# NAVSS0_MAILBOX1_10_ALIAS64K_MAILBOX1_CFG_REGS10 register map
Vendor: Texas Instruments
Peripheral module from a debugger description file (folder J721S2).
Registers are 32-bit, read-write, reset 0x0 unless marked. A register's access mark holds for its fields unless they carry their own. Offsets are as the file gives them; lines under a group give offsets from that group; [hi:lo] are bit positions; {n}, {i} and the like mark numbered series; 'fields as' and 'values as' point back to an identical list; <NAME> marks a mode.

## NAVSS0_MAILBOX1_10_ALIAS64K_MAILBOX1_CFG_REGS10
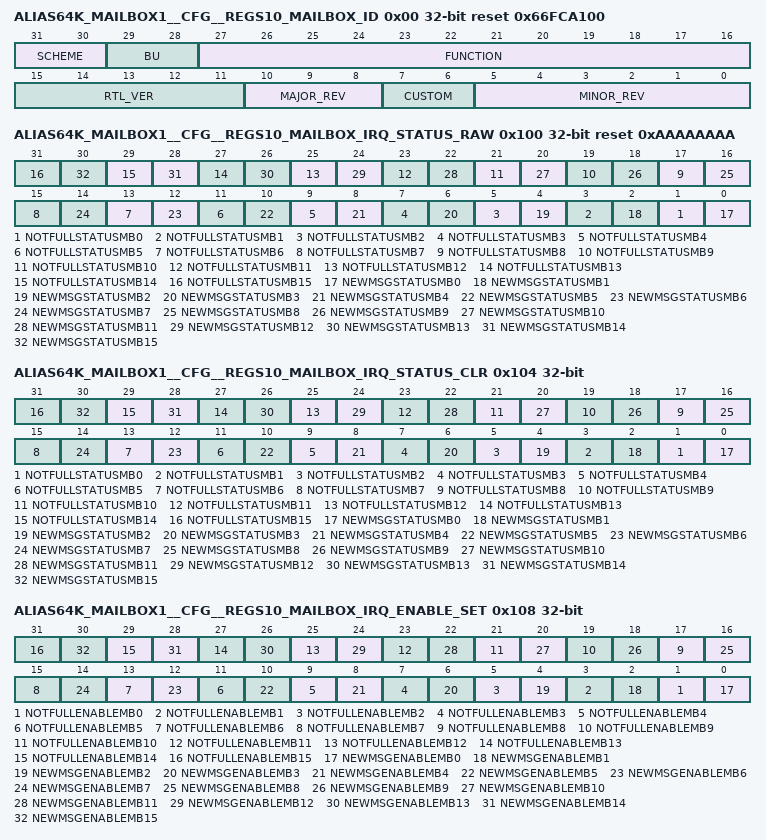
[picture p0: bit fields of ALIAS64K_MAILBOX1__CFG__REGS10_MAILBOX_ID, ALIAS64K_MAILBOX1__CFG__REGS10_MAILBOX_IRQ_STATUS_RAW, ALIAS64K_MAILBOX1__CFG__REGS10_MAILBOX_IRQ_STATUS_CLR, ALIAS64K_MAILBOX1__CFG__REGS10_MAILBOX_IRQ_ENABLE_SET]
0x00 ALIAS64K_MAILBOX1__CFG__REGS10_MAILBOX_ID ro reset 0x66FCA100 — This is the standard TI peripheral ID register that exists at address 0 in the peripheral space
  [31:30] SCHEME — Used to distinguish which ID numbering scheme is used.
  [29:28] BU — BU identifier
  [27:16] FUNCTION — Module family.
  [15:11] RTL_VER — RTL version. R of X.Y.R.Z
  [10:8] MAJOR_REV — Major revision. X of X.Y.R.Z
  [7:6] CUSTOM — Special version number
  [5:0] MINOR_REV — Minor revision. Y of X.Y.R.Z
0x10 ALIAS64K_MAILBOX1__CFG__REGS10_MAILBOX_SYSCONFIG — This register contains parameters to control the whole Mailbox system. Provided for backwards compatibility with OMAP Mailbox. Only contains the soft reset.
  [0] SOFT_RESET — Module Software Reset The bit is automatically reset by the hardware. During reads, it always returns 0. It has the same effect as the hardware reset. Writing a 0 has no effect. Writing a 1 will start a soft reset sequence and empty all the mailboxes
0x40 ALIAS64K_MAILBOX1__CFG__REGS10_MAILBOX_MESSAGE — The message register stores the next to-be-read message of the mailbox. Read: Reads the next available message. Write: Add a message to this mailbox queue.
  [31:0] MESSAGE_VALUE — Message in Mailbox [a]
0x80 ALIAS64K_MAILBOX1__CFG__REGS10_MAILBOX_FIFOSTATUS ro — The FIFO status register has the status of the Mailbox[a] FIFO
  [0] FIFO_FULL — Full flag for Mailbox m
0xC0 ALIAS64K_MAILBOX1__CFG__REGS10_MAILBOX_MSGSTATUS ro — The message status register has the status of the messages in Mailbox[a]
  [2:0] NUM_MESSAGES — Number of messages in Mailbox[a]
0x100 ALIAS64K_MAILBOX1__CFG__REGS10_MAILBOX_IRQ_STATUS_RAW reset 0xAAAAAAAA — The interrupt status register has the status for each event that may be responsible for the generation of an interrupt to the corresponding user . Software may also write 1 to a given bit to set this bit to test interrupt generation. It will activate the status bit for two cycles. This may still be masked, however. Write 0 has no effect.
  [2n+1] NOTFULLSTATUSMB{n} (n=0..15) — 1 if Mailbox {n} is not full
  [2n] NEWMSGSTATUSMB{n} (n=0..15) — 1 if there are messages present in Mailbox {n}
0x104 ALIAS64K_MAILBOX1__CFG__REGS10_MAILBOX_IRQ_STATUS_CLR — The interrupt status register has the status for each event that may be responsible for the generation of an interrupt to the corresponding user combined with the corresponding MASK information. Software may also write 1 to a given bit to clear this bit. However, if the hardware still has pending, enabled events, the interrupt will fire again in two cycles. Write 0 has no effect.
  [2n+1] NOTFULLSTATUSMB{n} (n=0..15) — 1 if Mailbox {n} is not full and this interrupt bit is enabled
  [2n] NEWMSGSTATUSMB{n} (n=0..15) — 1 if there are messages present in Mailbox {n} and this interrupt bit is enabled
0x108 ALIAS64K_MAILBOX1__CFG__REGS10_MAILBOX_IRQ_ENABLE_SET — The interrupt enable register allows software to mask/unmask the module internal source of interrupt for the user [a]. Read value is the current enable bits for each interrupt source. Write 1 to a bit enables an interrupt source. Write 0 has no effect.
  [2n+1] NOTFULLENABLEMB{n} (n=0..15) — Read value is current enable state for this interrupt. Write 1 enables the interrupt. Write 0 does nothing.
  [2n] NEWMSGENABLEMB{n} (n=0..15) — Read value is current enable state for this interrupt. Write 1 enables the interrupt. Write 0 does nothing.
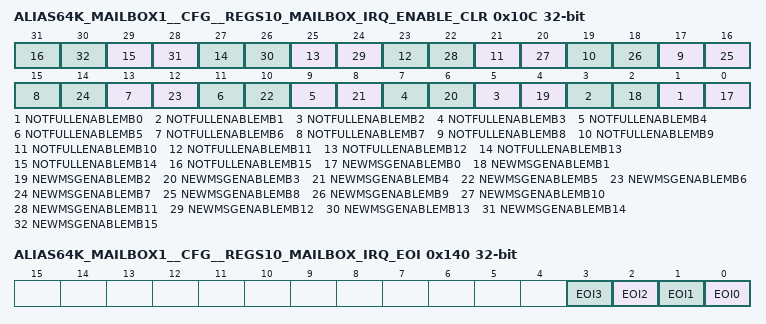
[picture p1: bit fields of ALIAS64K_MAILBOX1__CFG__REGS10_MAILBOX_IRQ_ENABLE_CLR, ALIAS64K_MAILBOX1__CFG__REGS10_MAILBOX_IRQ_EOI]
0x10C ALIAS64K_MAILBOX1__CFG__REGS10_MAILBOX_IRQ_ENABLE_CLR — The interrupt enable register allows software to mask/unmask the module internal source of interrupt for the user [a]. Read value is the current enable bits for each interrupt sourc. Write 1 to a bit disables an interrupt source. Write 0 has no effect.
  [2n+1] NOTFULLENABLEMB{n} (n=0..15) — Read value is current enable state for this interrupt. Write 1 disables the interrupt. Write 0 does nothing.
  [2n] NEWMSGENABLEMB{n} (n=0..15) — Read value is current enable state for this interrupt. Write 1 disables the interrupt. Write 0 does nothing.
0x140 ALIAS64K_MAILBOX1__CFG__REGS10_MAILBOX_IRQ_EOI wo — This is the EOI register with which the software is enabled to do the interrupt clearance.
  [n] EOI{n} (n=0..3) — Software EOI signal for the user {n} interrupt
